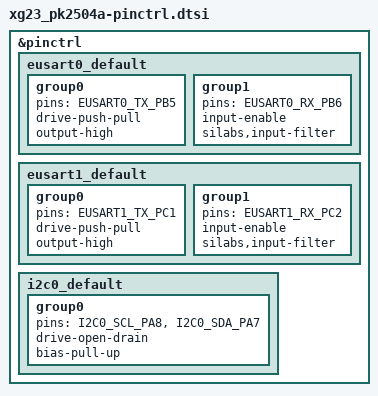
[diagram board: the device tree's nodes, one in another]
/*
 * Copyright (c) 2025 Christoph Jans
 *
 * SPDX-License-Identifier: Apache-2.0
 */

#include <dt-bindings/pinctrl/silabs/xg23-pinctrl.h>

&pinctrl {
	eusart0_default: eusart0_default {
		group0 {
			pins = <EUSART0_TX_PB5>;
			drive-push-pull;
			output-high;
		};

		group1 {
			pins = <EUSART0_RX_PB6>;
			input-enable;
			silabs,input-filter;
		};
	};

	eusart1_default: eusart1_default {
		group0 {
			pins = <EUSART1_TX_PC1>; //<EUSART1_TX_PB5>;
			drive-push-pull;
			output-high;
		};

		group1 {
			pins = <EUSART1_RX_PC2>; //<EUSART1_RX_PB6>;
			input-enable;
			silabs,input-filter;
		};
	};

	i2c0_default: i2c0_default {
		group0 {
			pins = <I2C0_SCL_PA8>, <I2C0_SDA_PA7>;
			drive-open-drain;
			bias-pull-up;
		};
	};
};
